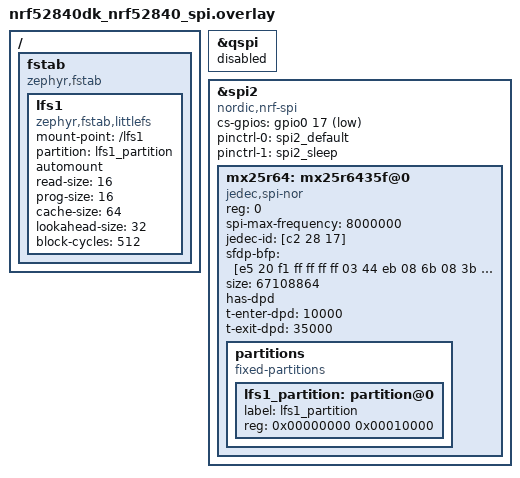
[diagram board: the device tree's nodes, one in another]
/*
 * Copyright (c) 2023 Nordic Semiconductor ASA
 *
 * SPDX-License-Identifier: Apache-2.0
 */

/delete-node/ &mx25r64;

&qspi {
	status = "disabled";
};

/* The mx25, on nrf52840dk/nrf52840, uses pins for spi0, spi1, spi2 and spi3
 * to provide quad-spi feature. In individual specifications each of the spi
 * notes define own clock source (SCK), but spi2 shares the same clock source
 * as qspi configuration, which is pin (0,19). That is why spi2 is used here
 * to communicate with mx25, when qspi is not used, to avoid rerouting clock
 * pin.
 */
&spi2 {
	compatible = "nordic,nrf-spi";
	status = "okay";
	cs-gpios = <&gpio0 17 GPIO_ACTIVE_LOW>;
	pinctrl-0 = <&spi2_default>;
	pinctrl-1 = <&spi2_sleep>;
	pinctrl-names = "default", "sleep";
	mx25r64: mx25r6435f@0 {
		compatible = "jedec,spi-nor";
		reg = <0>;
		spi-max-frequency = <8000000>;
		jedec-id = [c2 28 17];
		sfdp-bfp = [e5 20 f1 ff ff ff ff 03 44 eb 08 6b 08 3b 04 bb
			    ee ff ff ff ff ff 00 ff ff ff 00 ff 0c 20 0f 52
			    10 d8 00 ff 23 72 f5 00 82 ed 04 cc 44 83 68 44
			    30 b0 30 b0 f7 c4 d5 5c 00 be 29 ff f0 d0 ff ff];
		size = <67108864>;
		has-dpd;
		t-enter-dpd = <10000>;
		t-exit-dpd = <35000>;
	};
};

&mx25r64 {
	partitions {
		compatible = "fixed-partitions";
		#address-cells = <1>;
		#size-cells = <1>;

		lfs1_partition: partition@0 {
			label = "lfs1_partition";
			reg = <0x00000000 0x00010000>;
		};
	};
};

/ {
	fstab {
		compatible = "zephyr,fstab";
		lfs1: lfs1 {
			compatible = "zephyr,fstab,littlefs";
			mount-point = "/lfs1";
			partition = <&lfs1_partition>;
			automount;
			read-size = <16>;
			prog-size = <16>;
			cache-size = <64>;
			lookahead-size = <32>;
			block-cycles = <512>;
		};
	};
};
